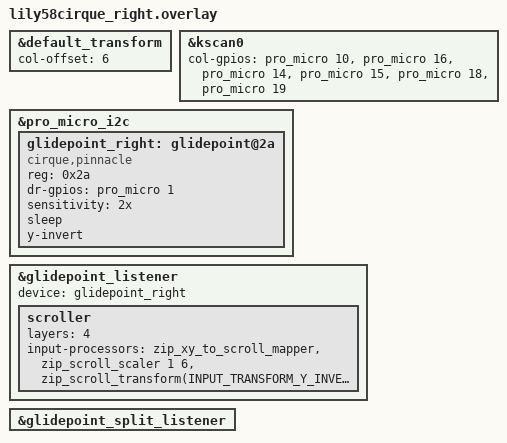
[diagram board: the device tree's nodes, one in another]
/*
 * Copyright (c) 2020 Pete Johanson
 *
 * SPDX-License-Identifier: MIT
 */

#include "lily58cirque.dtsi"
#include <input/processors.dtsi>
#include <dt-bindings/zmk/input_transform.h>

&default_transform {
    col-offset = <6>;
};

&kscan0 {
    col-gpios
        = <&pro_micro 10 GPIO_ACTIVE_HIGH>
        , <&pro_micro 16 GPIO_ACTIVE_HIGH>
        , <&pro_micro 14 GPIO_ACTIVE_HIGH>
        , <&pro_micro 15 GPIO_ACTIVE_HIGH>
        , <&pro_micro 18 GPIO_ACTIVE_HIGH>
        , <&pro_micro 19 GPIO_ACTIVE_HIGH>
        ;
};

&pro_micro_i2c {
    status = "okay";

    glidepoint_right: glidepoint@2a {
        compatible = "cirque,pinnacle";
        reg = <0x2a>;
        status = "okay";
        dr-gpios = <&pro_micro 1 (GPIO_ACTIVE_HIGH)>;
        sensitivity = "2x";
        sleep;
        //no-taps;
        y-invert;
        //x-invert;
    };
};

&glidepoint_listener {
    status = "okay";
    device = <&glidepoint_right>;

    /* BASE: cursor normal (sin processors extra) */

    /* Layer 4: scroll */
    scroller {
        layers = <4>;
        input-processors = <
            &zip_xy_to_scroll_mapper
            &zip_scroll_scaler 1 6
            &zip_scroll_transform(INPUT_TRANSFORM_Y_INVERT)
        >;
    };
};

&glidepoint_split_listener {
    status = "okay";
};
